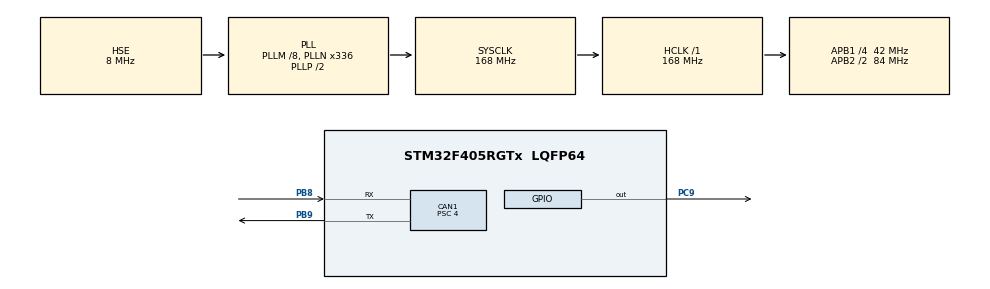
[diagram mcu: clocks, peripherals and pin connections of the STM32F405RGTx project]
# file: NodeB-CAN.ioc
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CAN1.BS1=CAN_BS1_16TQ
CAN1.BS2=CAN_BS2_4TQ
CAN1.CalculateBaudRate=500000
CAN1.CalculateTimeBit=2000
CAN1.CalculateTimeQuantum=95.23809523809524
CAN1.NART=ENABLE
CAN1.Prescaler=4
Mcu.Family=STM32F4
Mcu.Name=STM32F405RGTx
Mcu.Package=LQFP64
NVIC.CAN1_RX0_IRQn=true\:0\:0\:false\:false\:true\:true\:true\:true
NVIC.PriorityGroup=NVIC_PRIORITYGROUP_4
PB8.Mode=CAN_Activate
PB8.Signal=CAN1_RX
PB9.Mode=CAN_Activate
PB9.Signal=CAN1_TX
PC9.Signal=GPIO_Output
PH0-OSC_IN.Mode=HSE-External-Oscillator
PH0-OSC_IN.Signal=RCC_OSC_IN
PH1-OSC_OUT.Mode=HSE-External-Oscillator
PH1-OSC_OUT.Signal=RCC_OSC_OUT
ProjectManager.HeapSize=0x200
ProjectManager.StackSize=0x400
ProjectManager.TargetToolchain=Makefile
RCC.48MHZClocksFreq_Value=48000000
RCC.AHBFreq_Value=168000000
RCC.APB1CLKDivider=RCC_HCLK_DIV4
RCC.APB1Freq_Value=42000000
RCC.APB1TimFreq_Value=84000000
RCC.APB2CLKDivider=RCC_HCLK_DIV2
RCC.APB2Freq_Value=84000000
RCC.APB2TimFreq_Value=168000000
RCC.CortexFreq_Value=168000000
RCC.EnbaleCSS=true
RCC.HCLKFreq_Value=168000000
RCC.HSE_VALUE=8000000
RCC.HSI_VALUE=16000000
RCC.LSE_VALUE=32768
RCC.PLLM=8
RCC.PLLN=336
RCC.PLLQ=7
RCC.PLLSourceVirtual=RCC_PLLSOURCE_HSE
RCC.SYSCLKFreq_VALUE=168000000
RCC.SYSCLKSource=RCC_SYSCLKSOURCE_PLLCLK
RCC.VCOOutputFreq_Value=336000000
board=custom

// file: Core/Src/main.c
/* USER CODE BEGIN Header */
/**
  ******************************************************************************
  * @file           : main.c
  * @brief          : Main program body
  ******************************************************************************
  * @attention
  *
  * Copyright (c) 2026 STMicroelectronics.
  * All rights reserved.
  *
  * This software is licensed under terms that can be found in the LICENSE file
  * in the root directory of this software component.
  * If no LICENSE file comes with this software, it is provided AS-IS.
  *
  ******************************************************************************
  */
/* USER CODE END Header */
#include "main.h"

CAN_HandleTypeDef hcan1;

/* USER CODE BEGIN PV */
#define TYPE_STATUS   0x00
#define TYPE_CONTROL  0x01

#define CMD_LED_ON       0x01
#define CMD_LED_OFF      0x02
#define CMD_LED_TOGGLE   0x03
#define CMD_LED_BLINK    0x04

#define LED_MODE_OFF     0
#define LED_MODE_ON      1
#define LED_MODE_BLINK   2

volatile uint8_t led_mode = LED_MODE_OFF;

volatile uint32_t blink_on_ms = 0;
volatile uint32_t blink_off_ms = 0;

volatile uint32_t last_tick = 0;
volatile uint8_t led_state = 0;

volatile uint8_t status_update_pending = 0;
/* USER CODE END PV */

void SystemClock_Config(void);
static void MX_GPIO_Init(void);
static void MX_CAN1_Init(void);

/* USER CODE BEGIN 0 */
void Send_LED_Status(void)
{
    CAN_TxHeaderTypeDef txHeader;
    uint8_t data[8];
    uint32_t txMailbox;

    uint16_t status_id =
        (1 << 9) |
        (TYPE_STATUS << 6) |
        (2 << 3) |
        (1);

    txHeader.StdId = status_id;
    txHeader.ExtId = 0;
    txHeader.IDE   = CAN_ID_STD;
    txHeader.RTR   = CAN_RTR_DATA;
    txHeader.DLC   = 5;
    txHeader.TransmitGlobalTime = DISABLE;

    data[0] = led_mode;
    data[1] = (blink_on_ms >> 8) & 0xFF;
    data[2] = blink_on_ms & 0xFF;
    data[3] = (blink_off_ms >> 8) & 0xFF;
    data[4] = blink_off_ms & 0xFF;

    HAL_CAN_AddTxMessage(&hcan1, &txHeader, data, &txMailbox);
}
/* USER CODE END 0 */

int main(void)
{

  /* MCU Configuration--------------------------------------------------------*/

  /* Reset of all peripherals, Initializes the Flash interface and the Systick. */
  HAL_Init();

  /* Configure the system clock */
  SystemClock_Config();

  /* Initialize all configured peripherals */
  MX_GPIO_Init();
  MX_CAN1_Init();
  /* USER CODE BEGIN 2 */
  CAN_FilterTypeDef filter;

  // ------------------
  // Filter 0 → dest = 2
  // ------------------
  filter.FilterActivation = ENABLE;
  filter.FilterBank = 0;
  filter.FilterFIFOAssignment = CAN_FILTER_FIFO0;
  filter.FilterMode = CAN_FILTERMODE_IDMASK;
  filter.FilterScale = CAN_FILTERSCALE_32BIT;

  uint16_t dest_mask = 0x007;  // lowest 3 bits
  uint16_t dest_nodeB = 0x002; // destination = 2

  filter.FilterIdHigh     = (dest_nodeB << 5);
  filter.FilterIdLow      = 0x0000;
  filter.FilterMaskIdHigh = (dest_mask << 5);
  filter.FilterMaskIdLow  = 0x0000;

  HAL_CAN_ConfigFilter(&hcan1, &filter);

  // ------------------
  // Filter 1 → broadcast (dest = 0)
  // ------------------
  filter.FilterBank = 1;

  uint16_t dest_broadcast = 0x000;

  filter.FilterIdHigh     = (dest_broadcast << 5);
  filter.FilterIdLow      = 0x0000;
  filter.FilterMaskIdHigh = (dest_mask << 5);
  filter.FilterMaskIdLow  = 0x0000;

  if (HAL_CAN_ConfigFilter(&hcan1, &filter) != HAL_OK)
  {
      Error_Handler();
  }

  // 2️⃣ Start CAN
  if (HAL_CAN_Start(&hcan1) != HAL_OK)
  {
      Error_Handler();
  }

  // 3️⃣ Enable RX interrupt
  if (HAL_CAN_ActivateNotification(&hcan1, CAN_IT_RX_FIFO0_MSG_PENDING) != HAL_OK)
  {
      Error_Handler();
  }
  /* USER CODE END 2 */

  /* Infinite loop */
  /* USER CODE BEGIN WHILE */
  while (1)
  {
    uint32_t now = HAL_GetTick();

    switch (led_mode)
    {
        case LED_MODE_ON:
            HAL_GPIO_WritePin(GPIOC, GPIO_PIN_9, GPIO_PIN_SET);
            break;

        case LED_MODE_OFF:
            HAL_GPIO_WritePin(GPIOC, GPIO_PIN_9, GPIO_PIN_RESET);
            break;

        case LED_MODE_BLINK:

            if (led_state)
            {
                HAL_GPIO_WritePin(GPIOC, GPIO_PIN_9, GPIO_PIN_SET);

                if ((now - last_tick) >= blink_on_ms)
                {
                    led_state = 0;
                    last_tick = now;
                }
            }
            else
            {
                HAL_GPIO_WritePin(GPIOC, GPIO_PIN_9, GPIO_PIN_RESET);

                if ((now - last_tick) >= blink_off_ms)
                {
                    led_state = 1;
                    last_tick = now;
                }
            }
            break;
    }

    if (status_update_pending)
    {
        Send_LED_Status();
        status_update_pending = 0;
    }
    /* USER CODE END WHILE */

  }
}

void SystemClock_Config(void)
{
  RCC_OscInitTypeDef RCC_OscInitStruct = {0};
  RCC_ClkInitTypeDef RCC_ClkInitStruct = {0};

  /** Configure the main internal regulator output voltage
  */
  __HAL_RCC_PWR_CLK_ENABLE();
  __HAL_PWR_VOLTAGESCALING_CONFIG(PWR_REGULATOR_VOLTAGE_SCALE1);

  /** Initializes the RCC Oscillators according to the specified parameters
  * in the RCC_OscInitTypeDef structure.
  */
  RCC_OscInitStruct.OscillatorType = RCC_OSCILLATORTYPE_HSE;
  RCC_OscInitStruct.HSEState = RCC_HSE_ON;
  RCC_OscInitStruct.PLL.PLLState = RCC_PLL_ON;
  RCC_OscInitStruct.PLL.PLLSource = RCC_PLLSOURCE_HSE;
  RCC_OscInitStruct.PLL.PLLM = 8;
  RCC_OscInitStruct.PLL.PLLN = 336;
  RCC_OscInitStruct.PLL.PLLP = RCC_PLLP_DIV2;
  RCC_OscInitStruct.PLL.PLLQ = 7;
  if (HAL_RCC_OscConfig(&RCC_OscInitStruct) != HAL_OK)
  {
    Error_Handler();
  }

  /** Initializes the CPU, AHB and APB buses clocks
  */
  RCC_ClkInitStruct.ClockType = RCC_CLOCKTYPE_HCLK|RCC_CLOCKTYPE_SYSCLK
                              |RCC_CLOCKTYPE_PCLK1|RCC_CLOCKTYPE_PCLK2;
  RCC_ClkInitStruct.SYSCLKSource = RCC_SYSCLKSOURCE_PLLCLK;
  RCC_ClkInitStruct.AHBCLKDivider = RCC_SYSCLK_DIV1;
  RCC_ClkInitStruct.APB1CLKDivider = RCC_HCLK_DIV4;
  RCC_ClkInitStruct.APB2CLKDivider = RCC_HCLK_DIV2;

  if (HAL_RCC_ClockConfig(&RCC_ClkInitStruct, FLASH_LATENCY_5) != HAL_OK)
  {
    Error_Handler();
  }

  /** Enables the Clock Security System
  */
  HAL_RCC_EnableCSS();
}

static void MX_CAN1_Init(void)
{

  hcan1.Instance = CAN1;
  hcan1.Init.Prescaler = 4;
  hcan1.Init.Mode = CAN_MODE_NORMAL;
  hcan1.Init.SyncJumpWidth = CAN_SJW_1TQ;
  hcan1.Init.TimeSeg1 = CAN_BS1_16TQ;
  hcan1.Init.TimeSeg2 = CAN_BS2_4TQ;
  hcan1.Init.TimeTriggeredMode = DISABLE;
  hcan1.Init.AutoBusOff = DISABLE;
  hcan1.Init.AutoWakeUp = DISABLE;
  hcan1.Init.AutoRetransmission = ENABLE;
  hcan1.Init.ReceiveFifoLocked = DISABLE;
  hcan1.Init.TransmitFifoPriority = DISABLE;
  if (HAL_CAN_Init(&hcan1) != HAL_OK)
  {
    Error_Handler();
  }

}

static void MX_GPIO_Init(void)
{
  GPIO_InitTypeDef GPIO_InitStruct = {0};

  /* GPIO Ports Clock Enable */
  __HAL_RCC_GPIOH_CLK_ENABLE();
  __HAL_RCC_GPIOC_CLK_ENABLE();
  __HAL_RCC_GPIOB_CLK_ENABLE();

  /*Configure GPIO pin Output Level */
  HAL_GPIO_WritePin(GPIOC, GPIO_PIN_9, GPIO_PIN_RESET);

  /*Configure GPIO pin : PC9 */
  GPIO_InitStruct.Pin = GPIO_PIN_9;
  GPIO_InitStruct.Mode = GPIO_MODE_OUTPUT_PP;
  GPIO_InitStruct.Pull = GPIO_NOPULL;
  GPIO_InitStruct.Speed = GPIO_SPEED_FREQ_LOW;
  HAL_GPIO_Init(GPIOC, &GPIO_InitStruct);

}

/* USER CODE BEGIN 4 */
void HAL_CAN_RxFifo0MsgPendingCallback(CAN_HandleTypeDef *hcan)
{
    CAN_RxHeaderTypeDef rxHeader;
    uint8_t data[8];

    HAL_CAN_GetRxMessage(hcan, CAN_RX_FIFO0, &rxHeader, data);

    uint8_t type = (rxHeader.StdId >> 6) & 0x07;

    if (type != TYPE_CONTROL)
        return;

    if (rxHeader.DLC < 1)
        return;

    uint8_t cmd = data[0];

    switch (cmd)
    {
        case CMD_LED_ON:
            led_mode = LED_MODE_ON;
            status_update_pending = 1;
            break;

        case CMD_LED_OFF:
            led_mode = LED_MODE_OFF;
            status_update_pending = 1;
            break;

        case CMD_LED_TOGGLE:
            led_mode = (led_mode == LED_MODE_ON) ? LED_MODE_OFF : LED_MODE_ON;
            status_update_pending = 1;
            break;

        case CMD_LED_BLINK:
            if (rxHeader.DLC >= 5)
            {
                blink_on_ms  = (data[1] << 8) | data[2];
                blink_off_ms = (data[3] << 8) | data[4];

                led_mode = LED_MODE_BLINK;
                led_state = 1;
                last_tick = HAL_GetTick();

                status_update_pending = 1;
            }
            break;

        default:
            break;
    }
}
/* USER CODE END 4 */

void Error_Handler(void)
{
  __disable_irq();
  while (1)
  {
  }
}
